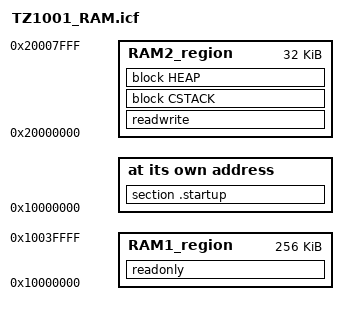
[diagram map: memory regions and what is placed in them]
/*###ICF### Section handled by ICF editor, don't touch! ****/
/*-Editor annotation file-*/
/* IcfEditorFile="$TOOLKIT_DIR$\config\ide\IcfEditor\a_v1_0.xml" */
/*-Specials-*/
define symbol __ICFEDIT_intvec_start__ = 0x00000000;
/*-Memory Regions-*/
define symbol __ICFEDIT_region_IROM1_start__ = 0x00000000;
define symbol __ICFEDIT_region_IROM1_end__   = 0x000fffff;
define symbol __ICFEDIT_region_IROM2_start__ = 0x0;
define symbol __ICFEDIT_region_IROM2_end__   = 0x0;
define symbol __ICFEDIT_region_EROM1_start__ = 0x0;
define symbol __ICFEDIT_region_EROM1_end__   = 0x0;
define symbol __ICFEDIT_region_EROM2_start__ = 0x0;
define symbol __ICFEDIT_region_EROM2_end__   = 0x0;
define symbol __ICFEDIT_region_EROM3_start__ = 0x0;
define symbol __ICFEDIT_region_EROM3_end__   = 0x0;
define symbol __ICFEDIT_region_IRAM1_start__ = 0x10000000;
define symbol __ICFEDIT_region_IRAM1_end__   = 0x1003FFFF;
define symbol __ICFEDIT_region_IRAM2_start__ = 0x20000000;
define symbol __ICFEDIT_region_IRAM2_end__   = 0x20007FFF;
define symbol __ICFEDIT_region_ERAM1_start__ = 0x0;
define symbol __ICFEDIT_region_ERAM1_end__   = 0x0;
define symbol __ICFEDIT_region_ERAM2_start__ = 0x0;
define symbol __ICFEDIT_region_ERAM2_end__   = 0x0;
define symbol __ICFEDIT_region_ERAM3_start__ = 0x0;
define symbol __ICFEDIT_region_ERAM3_end__   = 0x0;
/*-Sizes-*/
define symbol __ICFEDIT_size_cstack__ = 0x400;
define symbol __ICFEDIT_size_heap__   = 0x400;
/**** End of ICF editor section. ###ICF###*/

define symbol RAM_intvec_start         = 0x10000000;


define memory mem with size = 4G;
define region RAM1_region   = mem:[from __ICFEDIT_region_IRAM1_start__  to __ICFEDIT_region_IRAM1_end__];
define region RAM2_region   = mem:[from __ICFEDIT_region_IRAM2_start__  to __ICFEDIT_region_IRAM2_end__];

define block CSTACK    with alignment = 8, size = __ICFEDIT_size_cstack__   { };
define block HEAP      with alignment = 8, size = __ICFEDIT_size_heap__     { };

initialize by copy { readwrite };
do not initialize  { section .noinit };

//place at address mem:__ICFEDIT_intvec_start__ { section .intvec };
place at address mem:RAM_intvec_start         { section .startup };

place in RAM1_region   { readonly };
place in RAM2_region   { readwrite, block CSTACK, block HEAP };

/* 2015/01/27 *//* R0.1 */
